AUTOSAR XML (schema 4.0)
package /Battery_EV_Components
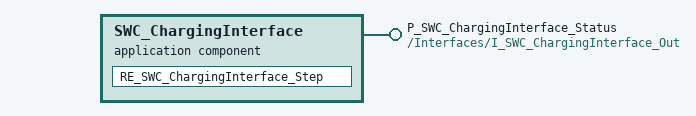
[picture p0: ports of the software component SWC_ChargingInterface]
  application sw component type SWC_ChargingInterface  # AUTOSAR Application SWC SWC_ChargingInterface for Battery EV Safety
    provide port P_SWC_ChargingInterface_Status: provided-interface=/Interfaces/I_SWC_ChargingInterface_Out
    behavior SWC_ChargingInterface_Behavior
      runnable RE_SWC_ChargingInterface_Step: symbol=SWC_ChargingInterface_Step
  sender receiver interface I_SWC_ChargingInterface_Out
    data DE_SWC_ChargingInterface_Health: type=/AUTOSAR/Platform/uint32
